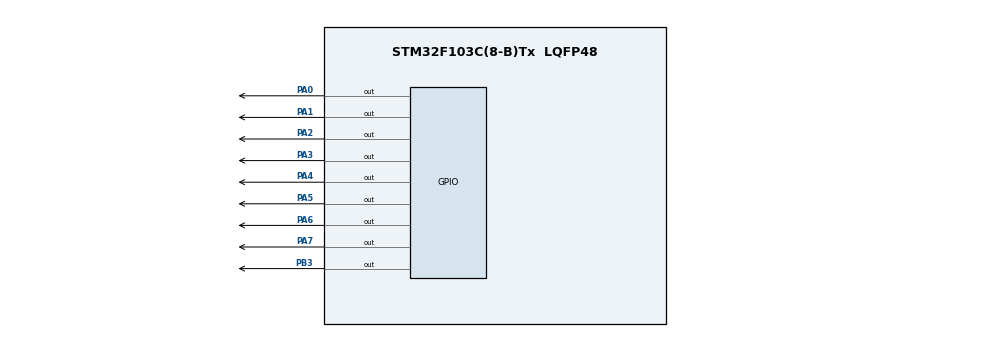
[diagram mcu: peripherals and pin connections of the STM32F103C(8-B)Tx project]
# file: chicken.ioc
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Mcu.Family=STM32F1
Mcu.Name=STM32F103C(8-B)Tx
Mcu.Package=LQFP48
NVIC.PriorityGroup=NVIC_PRIORITYGROUP_4
NVIC.TIM1_UP_IRQn=true\:0\:0\:false\:false\:true\:true\:true
NVIC.TIM3_IRQn=true\:0\:0\:false\:false\:true\:true\:true
PA0-WKUP.Signal=GPIO_Output
PA1.Signal=GPIO_Output
PA13.Mode=Serial_Wire
PA13.Signal=SYS_JTMS-SWDIO
PA14.Mode=Serial_Wire
PA14.Signal=SYS_JTCK-SWCLK
PA2.Signal=GPIO_Output
PA3.Signal=GPIO_Output
PA4.Signal=GPIO_Output
PA5.Signal=GPIO_Output
PA6.Signal=GPIO_Output
PA7.Signal=GPIO_Output
PB3.Signal=GPIO_Output
ProjectManager.HeapSize=0x200
ProjectManager.StackSize=0x400
ProjectManager.TargetToolchain=STM32CubeIDE
RCC.APB1Freq_Value=8000000
RCC.APB2Freq_Value=8000000
TIM1.Period=999
TIM1.Prescaler=8
TIM3.Period=999
TIM3.Prescaler=8
VP_TIM1_VS_ClockSourceINT.Mode=Internal
VP_TIM3_VS_ClockSourceINT.Mode=Internal
board=custom

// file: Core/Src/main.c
/* USER CODE BEGIN Header */
/**
  ******************************************************************************
  * @file           : main.c
  * @brief          : Main program body
  ******************************************************************************
  * @attention
  *
  * <h2><center>&copy; Copyright (c) 2020 STMicroelectronics.
  * All rights reserved.</center></h2>
  *
  * This software component is licensed by ST under BSD 3-Clause license,
  * the "License"; You may not use this file except in compliance with the
  * License. You may obtain a copy of the License at:
  *                        opensource.org/licenses/BSD-3-Clause
  *
  ******************************************************************************
  */
/* USER CODE END Header */
#include "main.h"
#include "tim.h"
#include "gpio.h"

/* USER CODE BEGIN Includes */
#include "thread.h"

/* USER CODE END Includes */

void SystemClock_Config(void);

int main(void)
{

  /* MCU Configuration--------------------------------------------------------*/

  /* Reset of all peripherals, Initializes the Flash interface and the Systick. */
  HAL_Init();

  /* Configure the system clock */
  SystemClock_Config();

  /* Initialize all configured peripherals */
  MX_GPIO_Init();
  MX_TIM1_Init();
  MX_TIM3_Init();
  /* USER CODE BEGIN 2 */

  HAL_TIM_Base_Start_IT(&htim1);

  RegisterThread(&BlinkBuzzer, 1000, ThreadRepeat, NULL);
  RegisterThread(&BlinkLed, 250, ThreadRepeat, NULL);

  /* USER CODE END 2 */

  /* Infinite loop */
  while (1)
  {

  }
}

void SystemClock_Config(void)
{
  RCC_OscInitTypeDef RCC_OscInitStruct = {0};
  RCC_ClkInitTypeDef RCC_ClkInitStruct = {0};

  /** Initializes the RCC Oscillators according to the specified parameters
  * in the RCC_OscInitTypeDef structure.
  */
  RCC_OscInitStruct.OscillatorType = RCC_OSCILLATORTYPE_HSI;
  RCC_OscInitStruct.HSIState = RCC_HSI_ON;
  RCC_OscInitStruct.HSICalibrationValue = RCC_HSICALIBRATION_DEFAULT;
  RCC_OscInitStruct.PLL.PLLState = RCC_PLL_NONE;
  if (HAL_RCC_OscConfig(&RCC_OscInitStruct) != HAL_OK)
  {
    Error_Handler();
  }
  /** Initializes the CPU, AHB and APB buses clocks
  */
  RCC_ClkInitStruct.ClockType = RCC_CLOCKTYPE_HCLK|RCC_CLOCKTYPE_SYSCLK
                              |RCC_CLOCKTYPE_PCLK1|RCC_CLOCKTYPE_PCLK2;
  RCC_ClkInitStruct.SYSCLKSource = RCC_SYSCLKSOURCE_HSI;
  RCC_ClkInitStruct.AHBCLKDivider = RCC_SYSCLK_DIV1;
  RCC_ClkInitStruct.APB1CLKDivider = RCC_HCLK_DIV1;
  RCC_ClkInitStruct.APB2CLKDivider = RCC_HCLK_DIV1;

  if (HAL_RCC_ClockConfig(&RCC_ClkInitStruct, FLASH_LATENCY_0) != HAL_OK)
  {
    Error_Handler();
  }
}

void Error_Handler(void)
{
}

/************************ (C) COPYRIGHT STMicroelectronics *****END OF FILE****/
